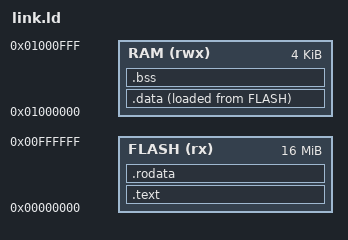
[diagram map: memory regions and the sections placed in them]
ENTRY(_start)

MEMORY
{
    FLASH (rx)  : ORIGIN = 0x00000000, LENGTH = 16M
    RAM   (rwx) : ORIGIN = 0x01000000, LENGTH = 4K
}

SECTIONS
{
    .text : {
        KEEP(*(.text.init))
        *(.text .text.*)
    } > FLASH

    .rodata : {
        *(.rodata .rodata.* .srodata .srodata.*)
    } > FLASH

    .data : ALIGN(4) {
        _data_start = .;
        *(.data .data.* .sdata .sdata.*)
        . = ALIGN(4);
        _data_end = .;
    } > RAM AT > FLASH
    _data_load = LOADADDR(.data);

    .bss (NOLOAD) : ALIGN(4) {
        _bss_start = .;
        *(.bss .bss.* .sbss .sbss.* COMMON)
        . = ALIGN(4);
        _bss_end = .;
    } > RAM

    _stack_top = ORIGIN(RAM) + LENGTH(RAM);

    /DISCARD/ : { *(.comment) *(.note .note.*) *(.eh_frame*) }
}
